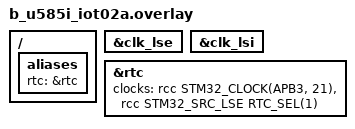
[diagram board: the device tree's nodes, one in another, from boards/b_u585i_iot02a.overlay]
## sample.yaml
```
sample:
  name: RTC usages example
tests:
  sample.board.stm32.rtc:
    tags: board
```

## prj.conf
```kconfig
CONFIG_RTC=y
```

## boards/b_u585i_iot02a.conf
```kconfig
CONFIG_COUNTER_RTC_STM32=y
CONFIG_COUNTER_TIMER_STM32=n

# build with counter_stm32_rtc driver else it builds the rtc_stm32 driver
CONFIG_COUNTER=y
```

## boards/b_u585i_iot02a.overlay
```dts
/ {
	aliases {
		rtc = &rtc;
	};
};

&clk_lse {
    status = "okay";
};

&clk_lsi {
    status = "okay";
};

&rtc {
    status = "okay";
    clocks = <&rcc STM32_CLOCK(APB3, 21)>,
/*		 <&rcc STM32_SRC_LSI RTC_SEL(2)>;*/
		 <&rcc STM32_SRC_LSE RTC_SEL(1)>;
    clock-names = "device" , "bus";
};
```

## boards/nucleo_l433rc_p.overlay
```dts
/ {
	aliases {
		rtc = &rtc;
	};
};

&clk_lse {
    status = "okay";
};

&rtc {
    status = "okay";
    clocks = <&rcc STM32_CLOCK(APB1, 28)>,
		 <&rcc STM32_SRC_LSE RTC_SEL(1)>;
    clock-names = "device" , "bus";
};
```

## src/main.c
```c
/*
 * Copyright (c) 2024, Muhammad Waleed Badar
 *
 * SPDX-License-Identifier: Apache-2.0
 */

#include <zephyr/kernel.h>
#include <zephyr/device.h>
#include <zephyr/drivers/rtc.h>
#include <zephyr/sys/util.h>
#include <zephyr/drivers/counter.h>

const struct device *const rtc = DEVICE_DT_GET(DT_ALIAS(rtc));

static int set_date_time(const struct device *rtc)
{
	int ret = 0;
	struct rtc_time tm = {
		.tm_year = 2026 - 1900,
		.tm_mon = 5,
		.tm_mday = 19,
		.tm_hour = 4,
		.tm_min = 19,
		.tm_sec = 0,
	};

	ret = rtc_set_time(rtc, &tm);
	if (ret < 0) {
		printk("Cannot write date time: %d\n", ret);
		return ret;
	}
	return ret;
}

static int get_date_time(const struct device *rtc)
{
	int ret = 0;
	struct rtc_time tm;

	ret = rtc_get_time(rtc, &tm);
	if (ret < 0) {
		printk("Cannot read date time: %d\n", ret);
		return ret;
	}

	printk("ticks=%02d\n",tm.tm_sec);

	return ret;
}

int main(void)
{
	/* Check if the RTC is ready */
	if (!device_is_ready(rtc)) {
		printk("Device is not ready\n");
		return 0;
	}
uint32_t time = 0;
	set_date_time(rtc);

	/* Continuously read the current date and time from the RTC */
	while(1) {
		(void)counter_get_value(rtc, &time);
		printk("ticks=%d\n",time);
		k_busy_wait( 10000000 );
	};

	return 0;
}
```
